# STM32F765 register map
File version: 1.7
CPU: CM7 r0p1, little endian, MPU, FPU, 4 interrupt priority bits
Registers are 32-bit, read-write, reset 0x0 unless marked. A register's access mark holds for its fields unless they carry their own. Offsets are from the block's base; [hi:lo] are bit positions; {n}, {i} and the like mark numbered series; 'fields as' and 'values as' point back to an identical list.

## DBGMCU — Debug support
Base 0xE0042000
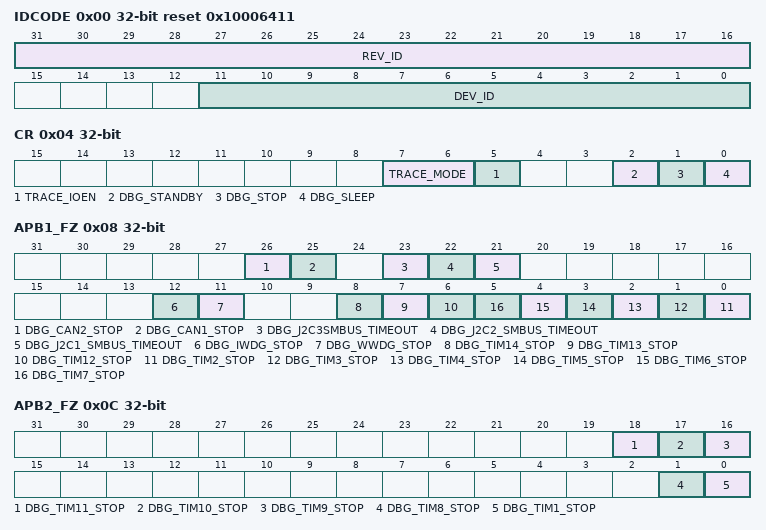
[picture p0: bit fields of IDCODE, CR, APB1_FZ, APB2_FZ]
0x00 IDCODE ro reset 0x10006411
  [31:16] REV_ID, [11:0] DEV_ID
0x04 CR — Control Register
  [7:6] TRACE_MODE, [5] TRACE_IOEN, [2] DBG_STANDBY, [1] DBG_STOP, [0] DBG_SLEEP
0x08 APB1_FZ — Debug MCU APB1 Freeze registe
  [26] DBG_CAN2_STOP
  [25] DBG_CAN1_STOP
  [23] DBG_J2C3SMBUS_TIMEOUT
  [22] DBG_J2C2_SMBUS_TIMEOUT
  [21] DBG_J2C1_SMBUS_TIMEOUT
  [12] DBG_IWDG_STOP — DBG_IWDEG_STOP
  [11] DBG_WWDG_STOP
  [8] DBG_TIM14_STOP
  [7] DBG_TIM13_STOP
  [6] DBG_TIM12_STOP
  [n-2] DBG_TIM{n}_STOP (n=2..7)
0x0C APB2_FZ — Debug MCU APB2 Freeze registe
  [18] DBG_TIM11_STOP — TIM11 counter stopped when core is halted
  [17] DBG_TIM10_STOP — TIM10 counter stopped when core is halted
  [16] DBG_TIM9_STOP — TIM9 counter stopped when core is halted
  [1] DBG_TIM8_STOP — TIM8 counter stopped when core is halted
  [0] DBG_TIM1_STOP — TIM1 counter stopped when core is halted

## SYSCFG — System configuration controller
Base 0x40013800
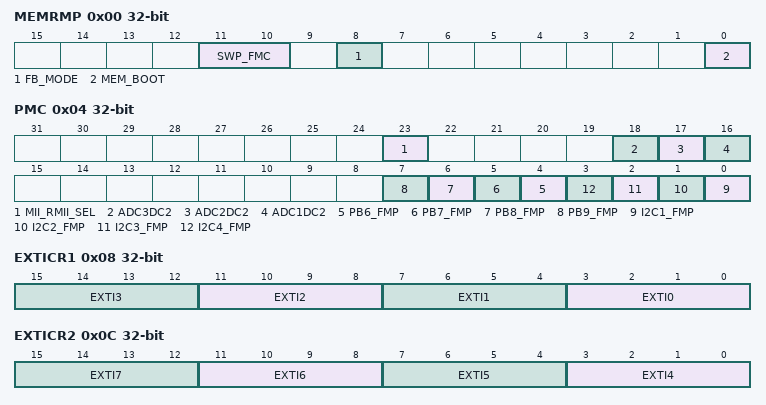
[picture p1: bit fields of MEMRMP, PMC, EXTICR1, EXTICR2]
0x00 MEMRMP — memory remap register
  [11:10] SWP_FMC — FMC memory mapping swap
  [8] FB_MODE — Flash bank mode selection
  [0] MEM_BOOT — Memory mapping selection
0x04 PMC — peripheral mode configuration register
  [23] MII_RMII_SEL — Ethernet PHY interface selection
  [18] ADC3DC2
  [17] ADC2DC2
  [16] ADC1DC2
  [n-2] PB{n}_FMP (n=6..9) — PB{n}_FMP Fast Mode + Enable
  [n-1] I2C{n}_FMP (n=1..4) — I2C{n} Fast Mode + Enable
0x08 EXTICR1 — external interrupt configuration register 1
  [4n+3:4n] EXTI{n} (n=0..3) — EXTI x configuration (x = 0 to 3)
0x0C EXTICR2 — external interrupt configuration register 2
  [4n-13:4n-16] EXTI{n} (n=4..7) — EXTI x configuration (x = 4 to 7)
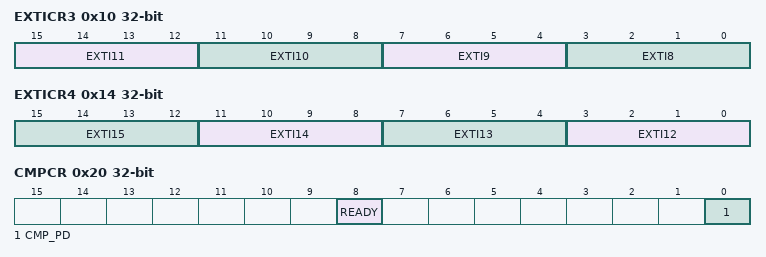
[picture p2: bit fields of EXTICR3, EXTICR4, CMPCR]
0x10 EXTICR3 — external interrupt configuration register 3
  [15:12] EXTI11 — EXTI x configuration (x = 8 to 11)
  [11:8] EXTI10
  [7:4] EXTI9 — EXTI x configuration (x = 8 to 11)
  [3:0] EXTI8 — EXTI x configuration (x = 8 to 11)
0x14 EXTICR4 — external interrupt configuration register 4
  [4n-45:4n-48] EXTI{n} (n=12..15) — EXTI x configuration (x = 12 to 15)
0x20 CMPCR ro — Compensation cell control register
  [8] READY
  [0] CMP_PD — Compensation cell power-down

## ADC_Common — Analog-to-Digital Converter
Base 0x40012300
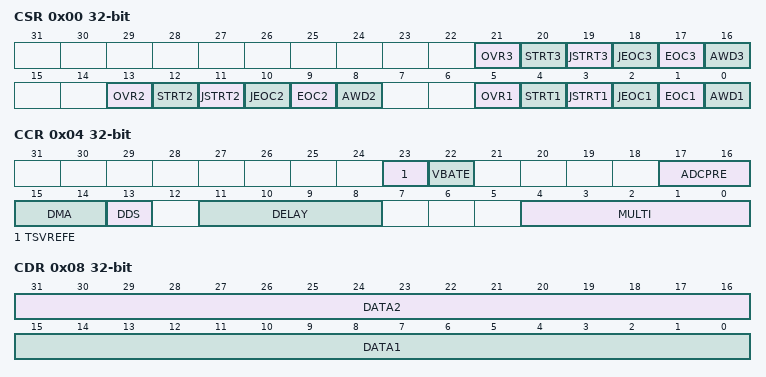
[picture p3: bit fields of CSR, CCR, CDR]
0x00 CSR ro — ADC Common status register
  [21] OVR3
    0=No overrun occurred; 1=Overrun occurred
  [20] STRT3
    0=NotStarted (No regular channel conversion started); 1=Started (Regular channel conversion has started)
  [19] JSTRT3
    0=NotStarted (No injected channel conversion started); 1=Started (Injected channel conversion has started)
  [18] JEOC3
    0=NotComplete (Conversion is not complete); 1=Complete (Conversion complete)
  [17] EOC3
    values as JEOC3
  [16] AWD3
    0=NoEvent (No analog watchdog event occurred); 1=Event (Analog watchdog event occurred)
  [13] OVR2
    0=No overrun occurred; 1=Overrun occurred
  [12] STRT2
    values as STRT3
  [11] JSTRT2
    values as JSTRT3
  [10] JEOC2
    values as JEOC3
  [9] EOC2
    values as JEOC3
  [8] AWD2
    values as AWD3
  [5] OVR1
    0=No overrun occurred; 1=Overrun occurred
  [4] STRT1
    values as STRT3
  [3] JSTRT1
    values as JSTRT3
  [2] JEOC1
    values as JEOC3
  [1] EOC1
    values as JEOC3
  [0] AWD1
    values as AWD3
0x04 CCR — ADC common control register
  [23] TSVREFE
    0=Disabled (Temperature sensor and V_REFINT channel disabled); 1=Enabled (Temperature sensor and V_REFINT channel enabled)
  [22] VBATE
    0=Disabled (V_BAT channel disabled); 1=Enabled (V_BAT channel enabled)
  [17:16] ADCPRE
    0=Div2 (PCLK2 divided by 2); 1=Div4 (PCLK2 divided by 4); 2=Div6 (PCLK2 divided by 6); 3=Div8 (PCLK2 divided by 8)
  [15:14] DMA
    0=Disabled (DMA mode disabled); 1=Mode1 (DMA mode 1 enabled (2 / 3 half-words one by one - 1 then 2 then 3)); 2=Mode2 (DMA mode 2 enabled (2 / 3 half-words by pairs - 2&1 then 1&3 then 3&2)); 3=Mode3 (DMA mode 3 enabled (2 / 3 half-words by pairs - 2&1 then 1&3 then 3&2))
  [13] DDS
    0=Single (No new DMA request is issued after the last transfer); 1=Continuous (DMA requests are issued as long as data are converted and DMA=01, 10 or 11)
  [11:8] DELAY
  [4:0] MULTI
    0=Independent (All the ADCs independent: independent mode); 1=DualRJ (Dual ADC1 and ADC2, combined regular and injected simultaneous mode); 2=DualRA (Dual ADC1 and ADC2, combined regular and alternate trigger mode); 5=DualJ (Dual ADC1 and ADC2, injected simultaneous mode only); 6=DualR (Dual ADC1 and ADC2, regular simultaneous mode only); 7=DualI (Dual ADC1 and ADC2, interleaved mode only); 9=Dual ADC1 and ADC2, alternate trigger mode only; 17=TripleRJ (Triple ADC, regular and injected simultaneous mode); 18=TripleRA (Triple ADC, regular and alternate trigger mode); 21=TripleJ (Triple ADC, injected simultaneous mode only); 22=TripleR (Triple ADC, regular simultaneous mode only); 23=TripleI (Triple ADC, interleaved mode only); 24=Triple ADC, alternate trigger mode only
0x08 CDR ro — ADC common regular data register for dual and triple modes
  [31:16] DATA2, [15:0] DATA1
